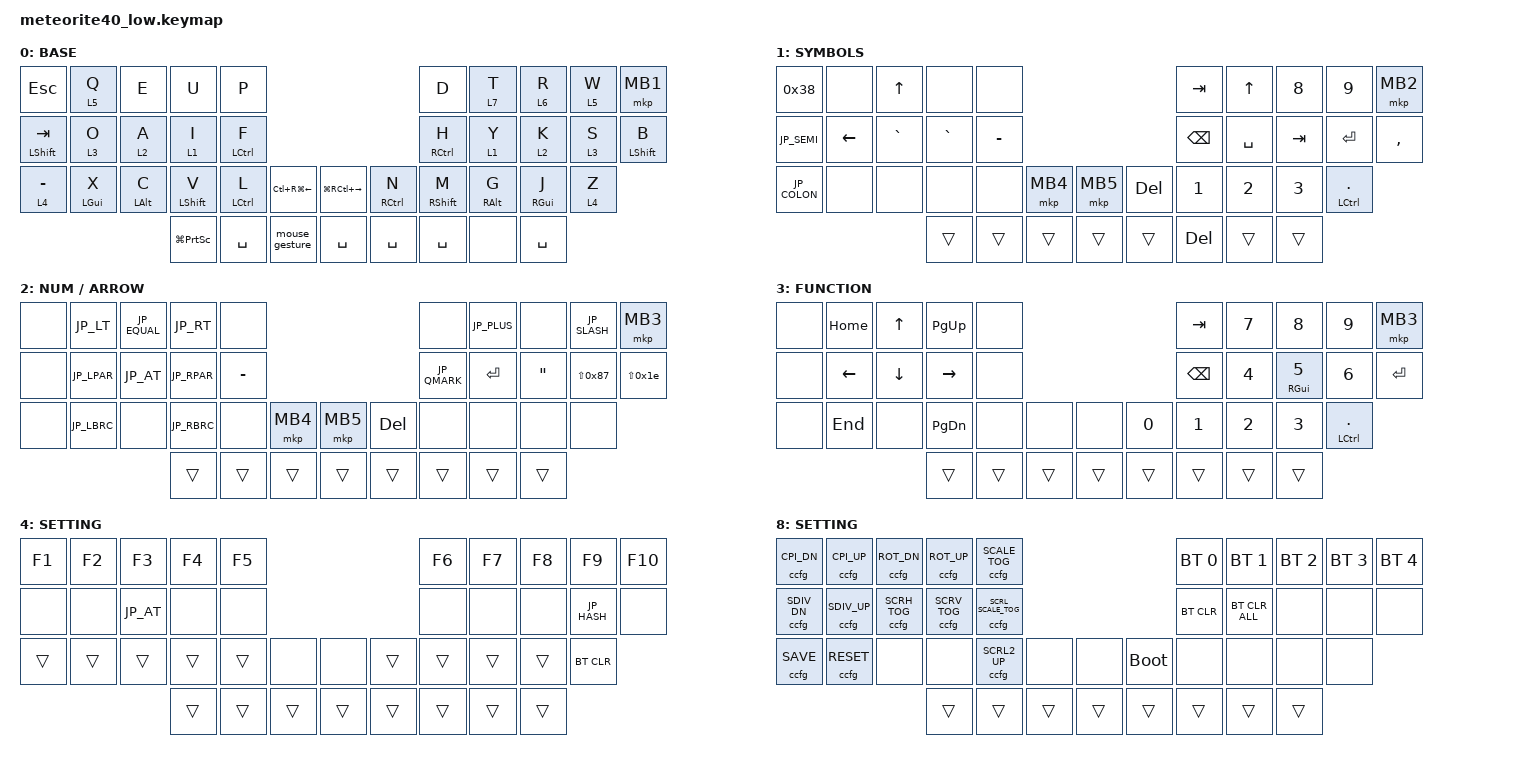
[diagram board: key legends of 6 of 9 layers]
#include <behaviors.dtsi>
#include <dt-bindings/zmk/bt.h>
#include <dt-bindings/zmk/keys.h>
#include <dt-bindings/zmk/pointing.h>

#include <behaviors/custom_config.dtsi>
#include <behaviors/meteorite_custom_key.dtsi>
#include <behaviors/meteorite_bt_os.dtsi>
#include <behaviors/meteorite_mod_key.dtsi>
#include <behaviors/meteorite_os_key.dtsi>
#include <dt-bindings/zmk/custom_config.h>
#include <dt-bindings/zmk/meteorite_custom_keys.h>
#include <dt-bindings/zmk/meteorite_bt_os.h>

#include "keycode_japanese.h"


#include <mouse-gesture.dtsi>


&msc {
    acceleration-exponent = <0>;      // 0
    time-to-max-speed-ms = <0>;       // 300
    delay-ms = <0>;                   // 0
};

&mmv {
    time-to-max-speed-ms = <0>;
    acceleration-exponent = <0>;
    trigger-period-ms = <10>;
    delay-ms = <0>;
};

&mt { 
    flavor = "balanced"; 
    tapping-term-ms = <200>;
    quick-tap-ms = <150>; 
};

&lt {
    flavor = "balanced";
    tapping-term-ms = <200>; 
    quick-tap-ms = <150>; 
};

&zip_mouse_gesture {
    stroke-size = <1>; // default: 200
    enable-eager-mode;
	idle-timeout-ms = <10>;
	gesture-cooldown-ms = <10>;

    right_space {
        pattern = <GESTURE_RIGHT>;
        bindings = <&kp RIGHT>;
    };

    left_space {
        pattern = <GESTURE_LEFT>;
        bindings = <&kp LEFT>;
    };

    mission_ctrl {
        pattern = <GESTURE_UP>;
        bindings = <&kp A>;
    };

    expose {
        pattern = <GESTURE_DOWN>;
        bindings = <&kp A>;
    };
};

//&trackball_listener {
//    compatible = "zmk,input-listener";
//    input-processors = <&zip_mouse_gesture>;
//};

    // 複数キーの同時押しに特別の入力を設定できる
    // キー番号早見表：
    // 0  1  2  3  4           5  6  7  8  9
    // 10 11 12 13 14          15 16 17 18 19
    // 20 21 22 23 24  25  26  27 28 29 30 31
    //      32 33 34   35  36  37 38 39



/ {


    combos {
        compatible = "zmk,combos";

//        combo_mouse_gester {
//            bindings = <&mouse_gesture>;
//            key-positions = <16 18>;
//            timeout-ms = <200>;
//        };

        line_home {
            bindings = <&mosk HOME LG(LEFT)>;
            key-positions = <16 17>; /* J + K (on layer 2) */
            layers = <2>;
        };

        line_end {
            bindings = <&mosk END LG(RIGHT)>;
            key-positions = <18 19>; /* L + - (on layer 2) */
            layers = <2>;
        };

//        doc_home {
//            bindings = <&mosk LC(HOME) LG(UP)>;
//            key-positions = <16 18>; /* J + L (on layer 2) */
//            layers = <2>;
//        };

        doc_end {
            bindings = <&mosk LC(END) LG(DOWN)>;
            key-positions = <17 19>; /* K + - (on layer 2) */
            layers = <2>;
       };


       hankaku {
            bindings = <&kp GRAVE>;
            key-positions = <1 3>;
            layers = <0>;
            timeout-ms = <200>;
        };

       hankaku-2 {
            bindings = <&kp GRAVE>;
            key-positions = <14 15>;
            layers = <0>;
            timeout-ms = <300>;
        };

        fopen {
            bindings = <&kp LG(N2)>;
            key-positions = <5 9>;
            layers = <0>;
            timeout-ms = <200>;
        };

       bootloader {
            bindings = <&bootloader>;
            key-positions = <0 9 20 31>;
            timeout-ms = <200>;
        };



        btcl {
            bindings = <&bt BT_CLR_ALL>;
            key-positions = <0 10 20>;
            layers = <0>;
        };

        bt0 {
            bindings = <&bt BT_SEL 0>;
            key-positions = <5 15 27>;
            layers = <0>;
        };

        bt1 {
            bindings = <&bt BT_SEL 1>;
            key-positions = <6 16 28>;
            layers = <0>;
        };

        bt2 {
            bindings = <&bt BT_SEL 2>;
            key-positions = <7 17 29>;
            layers = <0>;
        };

        mute {
            bindings = <&kp C_MUTE>;
            key-positions = <13 14>;
            layers = <0>;
        };

        vup {
            bindings = <&kp C_VOL_UP>;
            key-positions = <3 4>;
            layers = <0>;
        };

        vdn {
            bindings = <&kp C_VOL_DN>;
            key-positions = <23 24>;
            layers = <0>;
        };

        lspace{
            bindings = <&kp SPACE>;
            key-positions = <11 13>;
        };

    	mo_8{
            bindings = <&mo 8>;
            key-positions = <38 39>;
        };


    };





    keymap {
        compatible = "zmk,keymap";
        layout = &LOW_PROFILE_DEFAULT;

        win_default_layer {
            display-name = "BASE";
            bindings = <
&kp ESCAPE          &lt 5 Q        &kp E      &kp U         &kp P                                    &kp D        &lt 7 T         &lt 6 R       &lt 5 W       &mkp MB1
&mt LSHIFT TAB      &lt 3 O        &lt 2 A      &lt 1 I         &mt LCTRL F                             &mt RCTRL H  &lt 1 Y         &lt 2 K       &lt 3 S       &mt LEFT_SHIFT B
&lt 4 MINUS    &mt LGUI X   &mt LALT C &mt LSHIFT V  &mt LCTRL L       &kp LC(RG(LEFT))        &kp LG(RC(RIGHT))    &mt RCTRL N        &mt RSHIFT M  &mt RALT G  &mt RGUI J  &lt 4 Z
                                   &kp LG(PSCRN)     &kp SPACE  &mouse_gesture  &kp SPACE  &kp SPACE  &kp SPACE   &none  &kp SPACE
            >;
        };

        layer_1 {
            display-name = "SYMBOLS";
            bindings = <
&kp 0x38     &none      &kp UP     &none       &none                                 &kp TAB          &kp UP          &kp N8        &kp N9         &mkp MB2
&kp JP_SEMI  &kp LEFT   &kp GRAVE  &kp GRAVE   &kp MINUS                             &kp BACKSPACE  &kp SPACE       &kp TAB       &kp ENTER      &kp COMMA 
&kp JP_COLON &none      &none      &none       &none       &mkp MB4  &mkp MB5   &kp DELETE     &kp N1          &kp N2        &kp N3         &mt LCTRL PERIOD
                                     &trans     &trans    &trans    &trans    &trans     &kp DEL    &trans     &trans
            >;
        };

        layer_2 {
            display-name = "NUM / ARROW";
            bindings = <
&none        &kp JP_LT      &kp JP_EQUAL   &kp JP_RT  &none                                        &none          &kp JP_PLUS     &none        &kp JP_SLASH  &mkp MB3
&none        &kp JP_LPAR    &kp JP_AT      &kp JP_RPAR   &kp MINUS                                 &kp JP_QMARK   &kp ENTER  &kp DOUBLE_QUOTES &kp LS(0x87)  &kp LS(0x1e)
&none        &kp JP_LBRC    &none          &kp JP_RBRC   &none   &mkp MB4   &mkp MB5   &kp DELETE          &none           &none         &none         &none
                                        &trans           &trans     &trans     &trans    &trans        &trans  &trans    &trans
            >;
        };

        layer_3 {
            display-name = "FUNCTION";
            bindings = <
&none        &kp HOME   &kp UP     &kp PAGE_UP      &none                                 &kp TAB          &kp N7          &kp N8        &kp N9         &mkp MB3
&none        &kp LEFT   &kp DOWN   &kp RIGHT        &none                                 &kp BACKSPACE  &kp N4          &mt RGUI N5        &kp N6         &kp ENTER
&none        &kp END    &none      &kp PAGE_DOWN    &none   &none   &none   &kp N0         &kp N1          &kp N2        &kp N3         &mt LCTRL PERIOD
                                &trans  &trans  &trans  &trans  &trans  &trans  &trans  &trans
            >;
        };

        layer_4 {
			display-name = "SETTING";
			bindings = <
	&kp F1  &kp F2  &kp F3  &kp F4  &kp F5                  &kp F6  &kp F7  &kp F8  &kp F9  &kp F10
&none   &none   &kp JP_AT   &none   &none                   &none   &none   &none   &kp JP_HASH   &none
&trans  &trans  &trans  &trans  &trans         &none  &none    &trans        &trans        &trans        &trans        &bt BT_CLR
												               
&trans       &trans  &trans  &trans  &trans  &trans    &trans        &trans
			>;
        };






        5{
            bindings = <
&kp F1  &msc SCRL_RIGHT   &mmv MOVE_Y(-1500)     &msc SCRL_UP  &kp F5                  &kp F6  &kp F7  &kp F8  &kp F9  &mkp MB1
&none      &mmv MOVE_X(-1500) &mmv MOVE_Y(1500)    &mmv MOVE_X(1500)    &none                    &none   &none   &none   &kp JP_HASH   &none
&trans  &msc SCRL_LEFT   &trans           &msc SCRL_DOWN  &trans           &none  &none                           &trans        &trans        &trans        &trans        &bt BT_CLR

&none       &none   &none   &none   &none                                         &none          &none    &none   &none           &none
            >;
        };

        6{
            bindings = <
&kp F1  &msc SCRL_RIGHT   &mmv MOVE_Y(-900)     &msc SCRL_UP  &kp F5                  &kp F6  &kp F7  &kp F8  &kp F9  &mkp MB1
&none      &mmv MOVE_X(-900) &mmv MOVE_Y(900)    &mmv MOVE_X(900)    &none                    &none   &none   &none   &kp JP_HASH   &none
&trans  &msc SCRL_LEFT   &trans           &msc SCRL_DOWN  &trans             &none  &none                         &trans        &trans        &trans        &trans        &bt BT_CLR

&none       &none   &none   &none   &none                                         &none          &none    &none   &none           &none
            >;
        };

        7{
            bindings = <
&kp F1  &msc SCRL_RIGHT   &mmv MOVE_Y(-200)     &msc SCRL_UP  &kp F5                  &kp F6  &kp F7  &kp F8  &kp F9  &mkp MB1
&none      &mmv MOVE_X(-200) &mmv MOVE_Y(200)    &mmv MOVE_X(200)    &none                    &none   &none   &none   &kp JP_HASH   &none
&trans  &msc SCRL_LEFT   &trans           &msc SCRL_DOWN  &trans               &none  &none                       &trans        &trans        &trans        &trans        &bt BT_CLR

&none       &none   &none   &none   &none                                         &none          &none    &none   &none           &none
            >;
        };




        layer_8 {
			display-name = "SETTING";
			bindings = <
				&ccfg C_CPI_DN  &ccfg C_CPI_UP  &ccfg C_ROT_DN   &ccfg C_ROT_UP   &ccfg C_SCALE_TOG                        &bt BT_SEL 0   &bt BT_SEL 1    &bt BT_SEL 2  &bt BT_SEL 3  &bt BT_SEL 4
				&ccfg C_SDIV_DN &ccfg C_SDIV_UP &ccfg C_SCRH_TOG &ccfg C_SCRV_TOG &ccfg C_SCRL_SCALE_TOG                   &bt BT_CLR     &bt BT_CLR_ALL  &none         &none         &none
				&ccfg C_SAVE    &ccfg C_RESET   &none            &none            &ccfg C_SCRL2_UP         &none  &none    &bootloader    &none           &none         &none         &none
												                    &trans       &trans  &trans  &trans  &trans  &trans    &trans        &trans
			>;
        };







    };
};
